# STM32G474VET7 register map
File version: 1.0
STM32G474CBT3,STM32G474CBT6,STM32G474CBT7,STM32G474CBU3,STM32G474CBU6,STM32G474CBU7,STM32G474CCT3,STM32G474CCT6,STM32G474CCT7,STM32G474CCU3,STM32G474CCU6,STM32G474CCU7,STM32G474CET3,STM32G474CET6,STM32G474CET7,STM32G474CEU3,STM32G474CEU6,STM32G474CEU7,STM32G474MBT6,STM32G474MCT6,STM32G474MET3,STM32G474MET6,STM32G474MET7,STM32G474MEY3,STM32G474MEY6,STM32G474MEY7,STM32G474PBI6,STM32G474PCI6,STM32G474PEI6,STM32G474QBT6,STM32G474QCT6,STM32G474QET6,STM32G474RBT3,STM32G474RBT6,STM32G474RBT7,STM32G474RCT3,STM32G474RCT6,STM32G474RCT7,STM32G474RET3,STM32G474RET6,STM32G474RET7,STM32G474VBH3,STM32G474VBH6,STM32G474VBH7,STM32G474VBT3,STM32G474VBT6,STM32G474VBT7,STM32G474VCH6,STM32G474VCT6,STM32G474VEH3,STM32G474VEH6,STM32G474VEH7,STM32G474VET3,STM32G474VET6,STM32G474VET7
Registers are 32-bit, access not given, reset 0x0 unless marked. A register's access mark holds for its fields unless they carry their own. Offsets are from the block's base; lines under a group give offsets from that group; [hi:lo] are bit positions; {n}, {i} and the like mark numbered series; 'fields as' and 'values as' point back to an identical list; <NAME> marks a mode.

## Memory map
0x40000000 TIM2
0x40000400 TIM3
0x40000800 TIM4
0x40000C00 TIM5
0x40001000 TIM6
0x40001400 TIM7
0x40002000 CRS
0x40002400 TAMP
0x40002800 RTC
0x40002C00 WWDG
0x40003000 IWDG
0x40003800 SPI2
0x40003C00 SPI3
0x40004400 USART2
0x40004800 USART3
0x40004C00 UART4
0x40005000 UART5
0x40005400 I2C1
0x40005800 I2C2
0x40005C00 USB
0x40006400 FDCAN1
0x40006500 FDCAN_CONFIG
0x40006800 FDCAN2
0x40006C00 FDCAN3
0x40007000 PWR
0x40007800 I2C3
0x40007C00 LPTIM1
0x40008000 LPUART1
0x40008400 I2C4
0x4000A000 UCPD1
0x40010000 SYSCFG
0x40010030 VREFBUF
0x40010200 COMP1
0x40010204 COMP2
0x40010208 COMP3
0x4001020C COMP4
0x40010210 COMP5
0x40010214 COMP6
0x40010218 COMP7
0x40010300 OPAMP
0x40010300 OPAMP1
0x40010304 OPAMP2
0x40010308 OPAMP3
0x4001030C OPAMP4
0x40010310 OPAMP5
0x40010314 OPAMP6
0x40010400 EXTI
0x40012C00 TIM1
0x40013000 SPI1
0x40013400 TIM8
0x40013800 USART1
0x40013C00 SPI4
0x40014000 TIM15
0x40014400 TIM16
0x40014800 TIM17
0x40015000 TIM20
0x40015400 SAI1
0x40016800 HRTIM1
0x40016880 HRTIM1_TIMA
0x40016900 HRTIM1_TIMB
0x40016980 HRTIM1_TIMC
0x40016A00 HRTIM1_TIMD
0x40016A80 HRTIM1_TIME
0x40016B00 HRTIM1_TIMF
0x40016B80 HRTIM1_COMMON
0x40020000 DMA1
0x40020400 DMA2
0x40020800 DMAMUX1
0x40020C00 CORDIC
0x40021000 RCC
0x40021400 FMAC
0x40022000 FLASH
0x40023000 CRC
0x48000000 GPIOA
0x48000400 GPIOB
0x48000800 GPIOC
0x48000C00 GPIOD
0x48001000 GPIOE
0x48001400 GPIOF
0x48001800 GPIOG
0x50000000 ADC1
0x50000100 ADC2
0x50000300 ADC12_COMMON
0x50000400 ADC3
0x50000500 ADC4
0x50000600 ADC5
0x50000700 ADC345_COMMON
0x50000800 DAC
0x50000800 DAC1
0x50000C00 DAC2
0x50001000 DAC3
0x50001400 DAC4
0x50060800 RNG
0xA0000000 FMC_Bank1_R
0xA0000080 FMC_Bank3_R
0xA0000104 FMC_Bank1E_R
0xA0001000 QUADSPI
0xE0042000 DBGMCU

## TIM2
Base 0x40000000
Same registers: TIM3 0x40000400, TIM4 0x40000800, TIM5 0x40000C00, TIM6 0x40001000, TIM7 0x40001400, TIM1 0x40012C00, TIM8 0x40013400, TIM15 0x40014000, TIM16 0x40014400, TIM17 0x40014800, TIM20 0x40015000
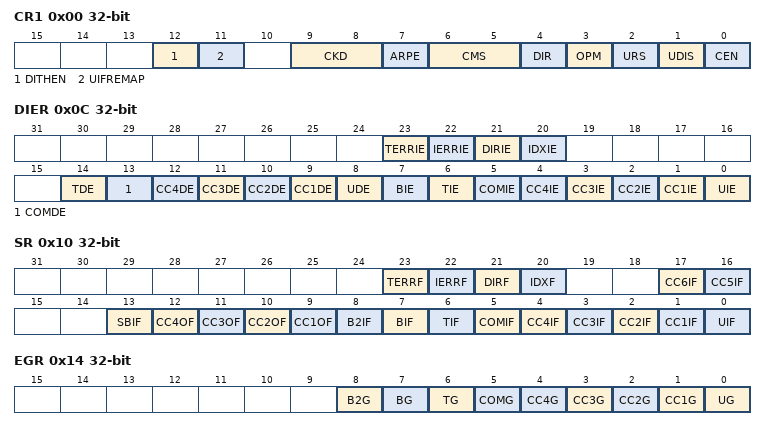
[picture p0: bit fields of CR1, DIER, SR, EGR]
0x00 CR1
  [12] DITHEN, [11] UIFREMAP, [9:8] CKD, [7] ARPE, [6:5] CMS, [4] DIR, [3] OPM, [2] URS, [1] UDIS, [0] CEN
0x04 CR2
  [23:20] MMS2, [2n+6] OIS{n} (n=1..6), [2n+7] OIS{n}N (n=1..4), [7] TI1S, [25:4] MMS, [3] CCDS, [2] CCUS, [0] CCPC
0x08 SMCR
  [25] SMSPS, [24] SMSPE, [15] ETP, [14] ECE, [13:12] ETPS, [11:8] ETF, [7] MSM, [21:4] TS, [3] OCCS, [16:0] SMS
0x0C DIER
  [23] TERRIE, [22] IERRIE, [21] DIRIE, [20] IDXIE, [14] TDE, [13] COMDE, [n+8] CC{n}DE (n=1..4), [8] UDE, [7] BIE, [6] TIE, [5] COMIE, [n] CC{n}IE (n=1..4), [0] UIE
0x10 SR
  [23] TERRF, [22] IERRF, [21] DIRF, [20] IDXF, [17] CC6IF, [16] CC5IF, [13] SBIF, [n+8] CC{n}OF (n=1..4), [8] B2IF, [7] BIF, [6] TIF, [5] COMIF, [n] CC{n}IF (n=1..4), [0] UIF
0x14 EGR
  [8] B2G, [7] BG, [6] TG, [5] COMG, [n] CC{n}G (n=1..4), [0] UG
0x18 CCMR1
  [15] OC2CE, [24:12] OC2M, [11] OC2PE, [10] OC2FE, [9:8] CC2S, [7] OC1CE, [16:4] OC1M, [3] OC1PE, [2] OC1FE, [1:0] CC1S
0x1C CCMR2
  [15] OC4CE, [24:12] OC4M, [11] OC4PE, [10] OC4FE, [9:8] CC4S, [7] OC3CE, [16:4] OC3M, [3] OC3PE, [2] OC3FE, [1:0] CC3S
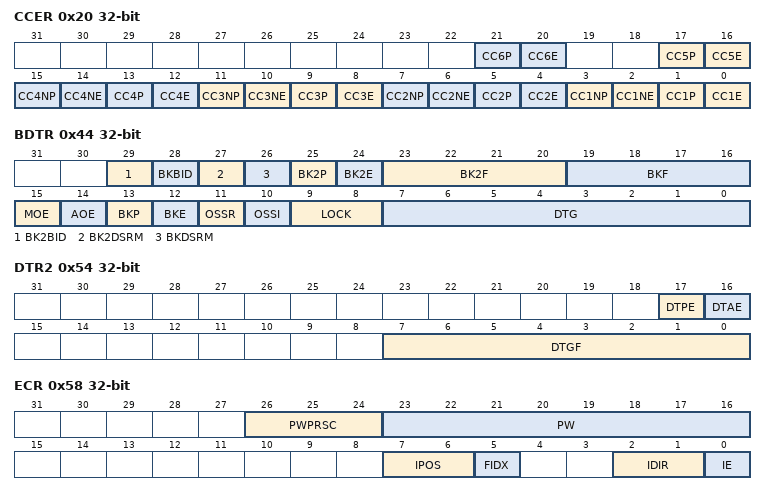
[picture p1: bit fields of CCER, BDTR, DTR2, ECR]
0x20 CCER
  [4n-3] CC{n}P (n=1..6), [4n-4] CC{n}E (n=1..6), [4n-1] CC{n}NP (n=1..4), [4n-2] CC{n}NE (n=1..4)
0x24 CNT
  [31] UIFCPY, [31:0] CNT
0x28 PSC
  [15:0] PSC
0x2C ARR
0x30 RCR
  [15:0] REP
{0x30+4i} CCR{i} (i=1..4)
  [15:0] CCR{i}
0x44 BDTR
  [29] BK2BID, [28] BKBID, [27] BK2DSRM, [26] BKDSRM, [25] BK2P, [24] BK2E, [23:20] BK2F, [19:16] BKF, [15] MOE, [14] AOE, [13] BKP, [12] BKE, [11] OSSR, [10] OSSI, [9:8] LOCK, [7:0] DTG
0x48 CCR5
  [31] GC5C3, [30] GC5C2, [29] GC5C1, [31:0] CCR5
0x4C CCR6
  [15:0] CCR6
0x50 CCMR3
  [15] OC6CE, [24:12] OC6M, [11] OC6PE, [10] OC6FE, [7] OC5CE, [16:4] OC5M, [3] OC5PE, [2] OC5FE
0x54 DTR2
  [17] DTPE, [16] DTAE, [7:0] DTGF
0x58 ECR
  [26:24] PWPRSC, [23:16] PW, [7:6] IPOS, [5] FIDX, [2:1] IDIR, [0] IE
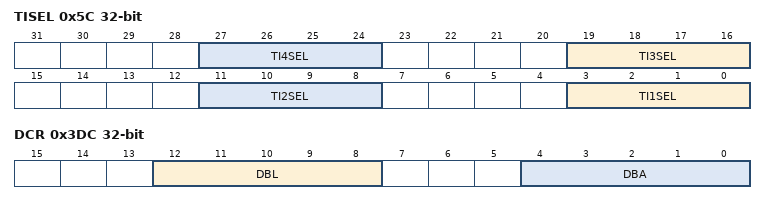
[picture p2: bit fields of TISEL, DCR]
0x5C TISEL
  [8n-5:8n-8] TI{n}SEL (n=1..4)
0x60 AF1
0x64 AF2
0x68 OR
  [0] HSE32EN
0x3DC DCR
  [12:8] DBL, [4:0] DBA
0x3E0 DMAR
  [31:0] DMAB
